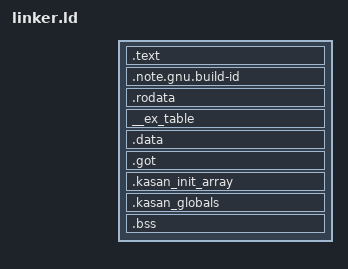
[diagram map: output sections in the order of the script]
/* linker.ld - 64-bit x86-64 linker script (Higher-half kernel, EFI stub boot) */
OUTPUT_FORMAT("elf64-x86-64")
OUTPUT_ARCH(i386:x86-64)

ENTRY(_start)

. = 0xFFFFFF8000100000;
SECTIONS {
    /* Code section — 4K-aligned start/end so paging.c can map .text as
       read-only 4K pages (W^X). Without page alignment the segment boundary
       falls inside a 2MB huge page shared with .data, so code pages can't be
       made RO independently and a wild write silently corrupts kernel
       instructions (observed: syscall_fast_entry bytes 00 00 -> FF FF -> #UD). */
    . = ALIGN(4096);
    __text_start = .;
    .text : AT(ADDR(.text) - 0xFFFFFF8000000000) {
        *(.text)
        *(.text.*)
    } :text
    . = ALIGN(4096);
    __text_end = .;

    .note.gnu.build-id : AT(ADDR(.note.gnu.build-id) - 0xFFFFFF8000000000) {
        __perf_build_id_note_start = .;
        KEEP(*(.note.gnu.build-id))
        __perf_build_id_note_end = .;
    } :rodata

    . = ALIGN(4096);
    __rodata_start = .;
    .rodata : AT(ADDR(.rodata) - 0xFFFFFF8000000000) {
        *(.rodata)
        *(.rodata.*)
    } :rodata

    /* Exception fixup table — (fault_rip, fixup_rip) pairs emitted by
       _ASM_EXTABLE in copy_user.c. Searched by fixup_exception() on
       kernel-mode #PF/#GP to rewind a user-copy and return -EFAULT. */
    __start___ex_table = .;
    __ex_table : AT(ADDR(__ex_table) - 0xFFFFFF8000000000) {
        KEEP(*(__ex_table))
    } :rodata
    __stop___ex_table = .;
    . = ALIGN(4096);
    __rodata_end = .;

    /*Initialized data section*/
    . = ALIGN(4096);
    __data_start = .;
    .data : AT(ADDR(.data) - 0xFFFFFF8000000000) {
        *(.data)
        *(.data.*)
        *(.data.rel.ro.local)
        *(.data.rel.ro)
        *(.data.rel.ro.*)
    } :data

    /* GOT section */
    .got : AT(ADDR(.got) - 0xFFFFFF8000000000) {
        *(.got)
        *(.got.plt)
    } :data

    /* Clang emits one ASan global-registration constructor per object. */
    .kasan_init_array : AT(ADDR(.kasan_init_array) - 0xFFFFFF8000000000) {
        __start_kasan_init_array = .;
        KEEP(*(.init_array.1))
        __stop_kasan_init_array = .;
    } :data

    /* GCC KASAN global variable redzone metadata. Keep the boundaries inside
       the output section so unrelated orphan sections cannot fall in range. */
    .kasan_globals : AT(ADDR(.kasan_globals) - 0xFFFFFF8000000000) {
        __start_kasan_globals = .;
        KEEP(*(__kasan_globals))
        __stop_kasan_globals = .;
    } :data

    . = ALIGN(4096);
    __data_end = .;
    /* Uninitialized data section (BSS) - 4KB aligned for page table use */
    .bss (NOLOAD) : AT(ADDR(.bss) - 0xFFFFFF8000000000) {
        *(.bss)
        *(.bss.*)
        *(COMMON)
    } :data

    kernel_end = .;

    /* Discard redundant sections auto-generated by the compiler */
    /DISCARD/ : {
        *(.eh_frame)
        *(.note.gnu.property)
        *(.comment)
    }
}

/* Explicit segmentation: code R+X, read-only R, data R+W, avoids RWX permission warnings on a single LOAD segment,
   and paves the way for page-level W^X/NX protection after paging is enabled */
PHDRS {
    text   PT_LOAD FLAGS(5);   /* R+X */
    rodata PT_LOAD FLAGS(4);   /* R   */
    data   PT_LOAD FLAGS(6);   /* R+W */
}
